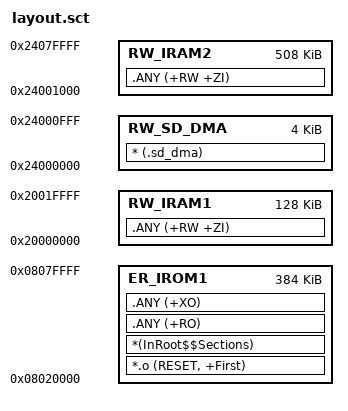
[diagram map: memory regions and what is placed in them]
; *************************************************************
; *** Scatter-Loading Description File generated by uVision ***
; *************************************************************

LR_IROM1 0x08020000 0x00060000  {    ; A/B应用固定执行地址，384KiB
  ER_IROM1 0x08020000 0x00060000  {
   *.o (RESET, +First)
   *(InRoot$$Sections)
   .ANY (+RO)
   .ANY (+XO)
  }
  RW_IRAM1 0x20000000 0x00020000  {  ; RW data
   .ANY (+RW +ZI)
  }
  RW_SD_DMA 0x24000000 0x00001000 {
    * (.sd_dma)
  }
  RW_IRAM2 0x24001000 0x0007F000  {
   .ANY (+RW +ZI)
  }
}

